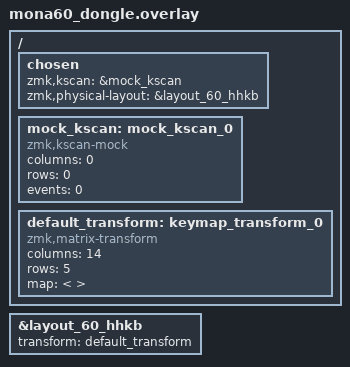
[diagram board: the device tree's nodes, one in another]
#include <dt-bindings/zmk/matrix_transform.h>
#include "hhkb.dtsi"

&layout_60_hhkb {
    transform = <&default_transform>;
};

/ {
    chosen {
        zmk,kscan = &mock_kscan;
        zmk,physical-layout = &layout_60_hhkb;
    };

    mock_kscan: mock_kscan_0 {
        compatible = "zmk,kscan-mock";
        columns = <0>;
        rows = <0>;
        events = <0>;
    };

    default_transform: keymap_transform_0 {
        compatible = "zmk,matrix-transform";
        columns = <14>;
        rows = <5>;

        map = <
        
            // Lots of RC(r,c) macros
        >;
    };
};
